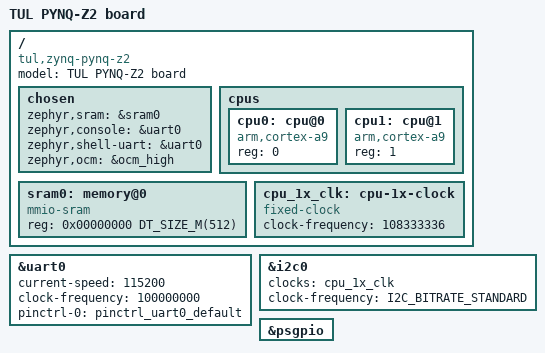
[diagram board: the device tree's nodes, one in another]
/*
 * Copyright (c) 2026 Radu Pirea
 *
 * SPDX-License-Identifier: Apache-2.0
 */

/dts-v1/;
#include <xilinx/zynq7000.dtsi>
#include <zephyr/dt-bindings/i2c/i2c.h>

#include "pynq_z2-pinctrl.dtsi"

/ {
	model = "TUL PYNQ-Z2 board";
	compatible = "tul,zynq-pynq-z2", "xlnx,zynq-7000";

	chosen {
		zephyr,sram = &sram0;
		zephyr,console = &uart0;
		zephyr,shell-uart = &uart0;
		zephyr,ocm = &ocm_high;
	};

	cpus {
		#address-cells = <1>;
		#size-cells = <0>;

		cpu0: cpu@0 {
			device_type = "cpu";
			compatible = "arm,cortex-a9";
			reg = <0>;
		};

		cpu1: cpu@1 {
			device_type = "cpu";
			compatible = "arm,cortex-a9";
			reg = <1>;
		};
	};

	sram0: memory@0 {
		compatible = "mmio-sram";
		reg = <0x00000000 DT_SIZE_M(512)>;
	};

	/* CPU_1x, derived from the ARM PLL with the PS configuration of the PYNQ-Z2 */
	cpu_1x_clk: cpu-1x-clock {
		compatible = "fixed-clock";
		clock-frequency = <108333336>;
		#clock-cells = <0>;
	};
};

&uart0 {
	status = "okay";
	current-speed = <115200>;
	clock-frequency = <100000000>;
	pinctrl-0 = <&pinctrl_uart0_default>;
	pinctrl-names = "default";
};

/*
 * Routed to the Raspberry Pi header (ID_SC/ID_SD) on MIO50/MIO51. The Cadence I2C driver has no
 * pinctrl support, so the MIO multiplexing is left to the PS initialization performed by the boot
 * loader (FSBL/U-Boot SPL).
 */
&i2c0 {
	status = "okay";
	clocks = <&cpu_1x_clk>;
	clock-frequency = <I2C_BITRATE_STANDARD>;
};

&psgpio {
	status = "okay";
};
